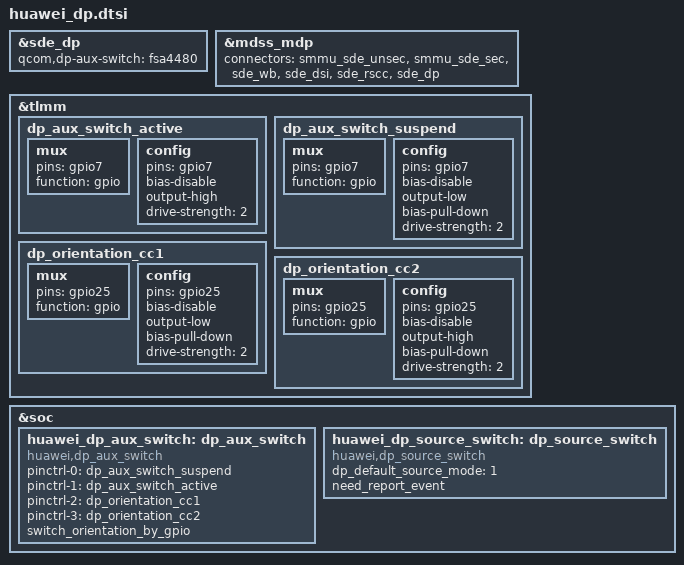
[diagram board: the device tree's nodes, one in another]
&sde_dp{
	status = "ok";
	qcom,dp-aux-switch = <&fsa4480>;
};

&mdss_mdp {
	connectors = <&smmu_sde_unsec &smmu_sde_sec &sde_wb &sde_dsi &sde_rscc &sde_dp>;
};

&tlmm {
	dp_aux_switch_active: dp_aux_switch_active {
		mux {
			pins = "gpio7";
			function = "gpio";
		};

		config {
			pins = "gpio7";
			bias-disable;
			output-high;
			drive-strength = <2>; /* 2 MA */
		};
	};

	dp_aux_switch_suspend: dp_aux_switch_suspend {
		mux {
			pins = "gpio7";
			function = "gpio";
		};

		config {
			pins = "gpio7";
			bias-disable;
			output-low;
			bias-pull-down; /* PULL DOWN */
			drive-strength = <2>; /* 2 MA */
		};
	};

	dp_orientation_cc1: dp_orientation_cc1 {
		mux {
			pins = "gpio25";
			function = "gpio";
		};

		config {
			pins = "gpio25";
			bias-disable;
			output-low;
			bias-pull-down; /* PULL DOWN */
			drive-strength = <2>; /* 2 MA */
		};
	};

	dp_orientation_cc2: dp_orientation_cc2 {
		mux {
			pins = "gpio25";
			function = "gpio";
		};

		config {
			pins = "gpio25";
			bias-disable;
			output-high;
			bias-pull-down; /* PULL DOWN */
			drive-strength = <2>; /* 2 MA */
		};
	};
};

&soc {
	huawei_dp_aux_switch: dp_aux_switch {
		compatible = "huawei,dp_aux_switch";
		pinctrl-names = "default", "aux_enable", "dp_cc1", "dp_cc2";
		pinctrl-0 = <&dp_aux_switch_suspend>;
		pinctrl-1 = <&dp_aux_switch_active>;
		pinctrl-2 = <&dp_orientation_cc1>;
		pinctrl-3 = <&dp_orientation_cc2>;
		switch_orientation_by_gpio;
		status = "ok";
	};

	huawei_dp_source_switch: dp_source_switch {
		compatible = "huawei,dp_source_switch";
		dp_default_source_mode = <1>; /* 0:diff mode 1:same mode */
		/* for MMIE test in factory version */
		need_report_event;
		status = "ok";
	};
};
